# PIC32CM5164JH00064 device description
Architecture: CORTEX-M0PLUS; Family: PIC32CM; Series: PIC32CMJH00
Registers are 32-bit, read-write, reset 0x0 unless marked. A register's access mark holds for its fields unless they carry their own. Offsets are from the block's base; [hi:lo] are bit positions; {n}, {i} and the like mark numbered series.

## MCRAMC — Multi-Channel RAM Controller
Instances: MCRAMC 0x40003000
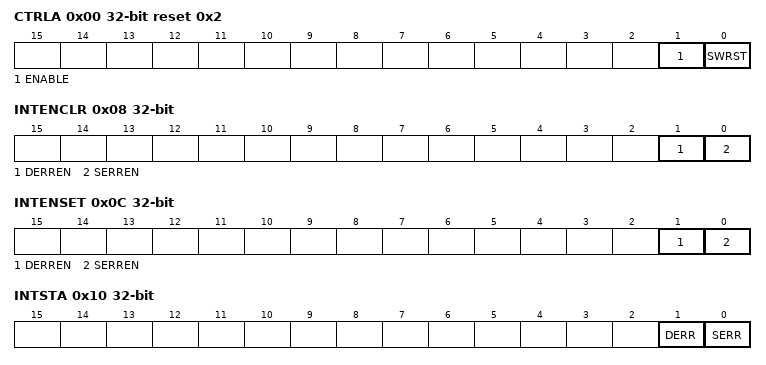
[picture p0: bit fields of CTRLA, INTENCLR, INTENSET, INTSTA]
0x00 CTRLA reset 0x2 — Control Enable A Register
  [1] ENABLE — ECC Decoder Enable
    0=ECC decoding is disabled; 1=ECC decoding is enabled
  [0] SWRST — Software Reset
    0=No effect; 1=Reset the MCRAMC. A software-triggered hardware reset of the MCRAMC user interface is performed.
0x08 INTENCLR (atomic clear) — Interrupt Enable Clear Register
  [1] DERREN — Double Bit Error Interrupt Enable, Clear
  [0] SERREN — Single Bit Error Interrupt Enable, Clear
0x0C INTENSET (atomic set) — Interrupt Enable Set Register
  [1] DERREN — Double Bit Error Interrupt Enable, Set
  [0] SERREN — Single Bit Error Interrupt Enable, Set
0x10 INTSTA (atomic clear) — Interrupt Status Register
  [1] DERR — Double Bit Error
  [0] SERR — Single Bit Error
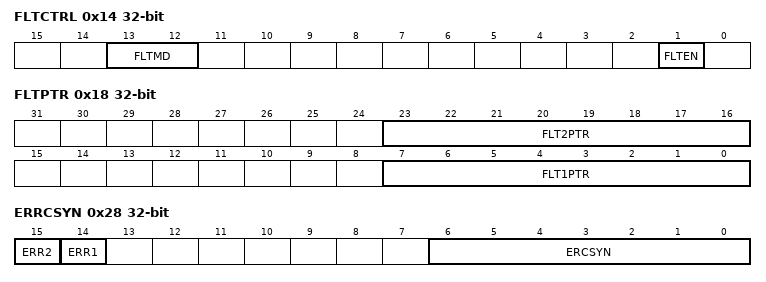
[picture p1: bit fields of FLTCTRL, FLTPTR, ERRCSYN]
0x14 FLTCTRL — Fault Injection Control Register
  [13:12] FLTMD — Fault Injection Mode
    0=DISABLE (Fault Injection Disabled); 1=SINGLE (Single Fault Injection at bit selected by FLTPTR.FTL1PTR); 2=DOUBLE (Double Fault Injection at bits FLTPTR.FTL1PTR and FLTPTR.FTL2PTR)
  [1] FLTEN — Fault Injection Enabled
    0=Disables fault injection; 1=Enables fault injection at FLTADR address offset as selected by FLTMD and FLTxPTR
0x18 FLTPTR — Fault Injection Pointer Register
  [23:16] FLT2PTR — Double Fault Injection Bit Pointer
  [7:0] FLT1PTR — Single Fault Injection Bit Pointer
0x1C FLTADR — Fault Injection Address Register
  [23:0] FLTADR — Fault Address Offset
0x20 ERRCADR ro — Error Capture Address Register
  [23:0] ERCADR — ECC SECDED Error Capture Address
0x24 ERRCPAR ro — Error Capture Parity Register
  [6:0] ERCPAR — ECC SECDED Error Capture Parity
0x28 ERRCSYN ro — Error Capture Syndrome Register
  [15] ERR2 — ECC Double Bit Error
    0=Not a Double bit error; 1=Double bit error
  [14] ERR1 — ECC Single Bit Error
  [6:0] ERCSYN — ECC SECDED Error Capture Syndrome
    0=Not a Single bit error; 1=Single bit error

## MPU — Memory Protection Unit
Instances: MPU 0xE000ED90
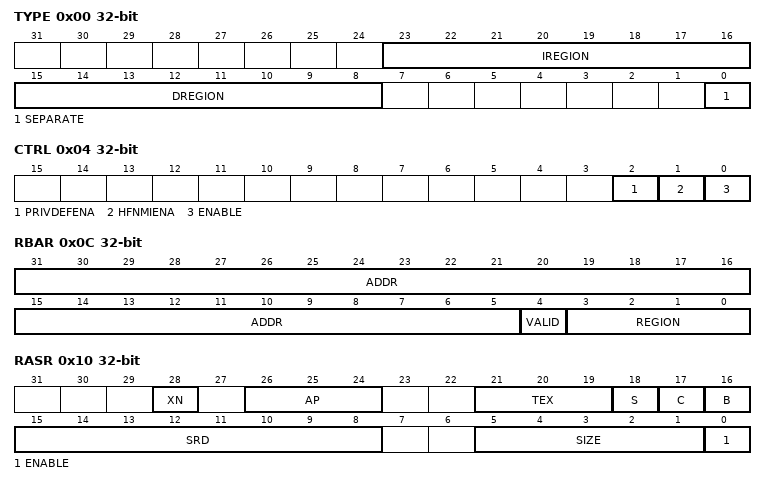
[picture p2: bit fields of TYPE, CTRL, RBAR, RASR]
0x00 TYPE ro reset not defined — MPU Type Register
  [23:16] IREGION — Number of Instruction Regions
  [15:8] DREGION — Number of Data Regions
  [0] SEPARATE — Separate instruction and Data Memory MapsRegions
0x04 CTRL reset not defined — MPU Control Register
  [2] PRIVDEFENA — Enables privileged software access to default memory map
  [1] HFNMIENA — Enable Hard Fault and NMI handlers
  [0] ENABLE — MPU Enable
0x08 RNR reset not defined — MPU Region Number Register
  [7:0] REGION — Region referenced by RBAR and RASR
0x0C RBAR reset not defined — MPU Region Base Address Register
  [31:5] ADDR — Region base address
  [4] VALID — Region number valid
  [3:0] REGION — Region number
0x10 RASR reset not defined — MPU Region Attribute and Size Register
  [28] XN — Execute Never Attribute
  [26:24] AP — Access Permission
  [21:19] TEX — TEX bit
  [18] S — Shareable bit
  [17] C — Cacheable bit
  [16] B — Bufferable bit
  [15:8] SRD — Sub-region disable
  [5:1] SIZE — Region Size
  [0] ENABLE — Region Enable

## MTB — Cortex-M0+ Micro-Trace Buffer
Instances: MTB 0x41008000
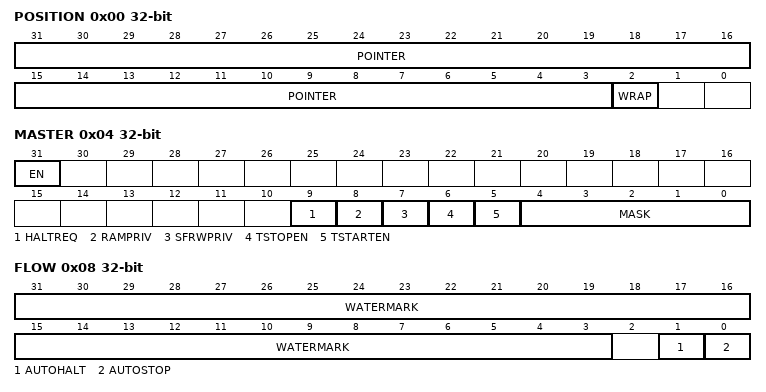
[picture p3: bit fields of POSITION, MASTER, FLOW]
0x00 POSITION reset not defined — MTB Position
  [31:3] POINTER — Trace Packet Location Pointer
  [2] WRAP — Pointer Value Wraps
0x04 MASTER — MTB Master
  [31] EN — Main Trace Enable
  [9] HALTREQ — Halt Request
  [8] RAMPRIV — SRAM Privilege
  [7] SFRWPRIV — Special Function Register Write Privilege
  [6] TSTOPEN — Trace Stop Input Enable
  [5] TSTARTEN — Trace Start Input Enable
  [4:0] MASK — Maximum Value of the Trace Buffer in SRAM
0x08 FLOW — MTB Flow
  [31:3] WATERMARK — Watermark value
  [1] AUTOHALT — Auto Halt Request
  [0] AUTOSTOP — Auto Stop Tracing
0x0C BASE ro reset not defined — MTB Base
0xF00 ITCTRL reset not defined — MTB Integration Mode Control
0xFA0 CLAIMSET reset not defined (atomic set) — MTB Claim Set
0xFA4 CLAIMCLR reset not defined (atomic clear) — MTB Claim Clear
0xFB0 LOCKACCESS reset not defined — MTB Lock Access
0xFB4 LOCKSTATUS ro reset not defined — MTB Lock Status
0xFB8 AUTHSTATUS ro reset not defined — MTB Authentication Status
0xFBC DEVARCH ro reset not defined — MTB Device Architecture
0xFC8 DEVID ro reset not defined — MTB Device Configuration
0xFCC DEVTYPE ro reset not defined — MTB Device Type
{0xFC0+4i} PID{i} ro reset not defined (i=4..7) — Peripheral Identification {i}
{0xFE0+4i} PID{i} ro reset not defined (i=0..3) — Peripheral Identification {i}
{0xFF0+4i} CID{i} ro reset not defined (i=0..3) — Component Identification {i}

## Notices in the file
Copyright (c) 2019 Microchip Technology Inc.
SPDX-License-Identifier: Apache-2.0
Licensed under the Apache License, Version 2.0 (the "License");
you may not use this file except in compliance with the License.
You may obtain a copy of the License at
http://www.apache.org/licenses/LICENSE-2.0
Unless required by applicable law or agreed to in writing, software
distributed under the License is distributed on an "AS IS" BASIS,
WITHOUT WARRANTIES OR CONDITIONS OF ANY KIND, either express or implied.
See the License for the specific language governing permissions and
limitations under the License.
